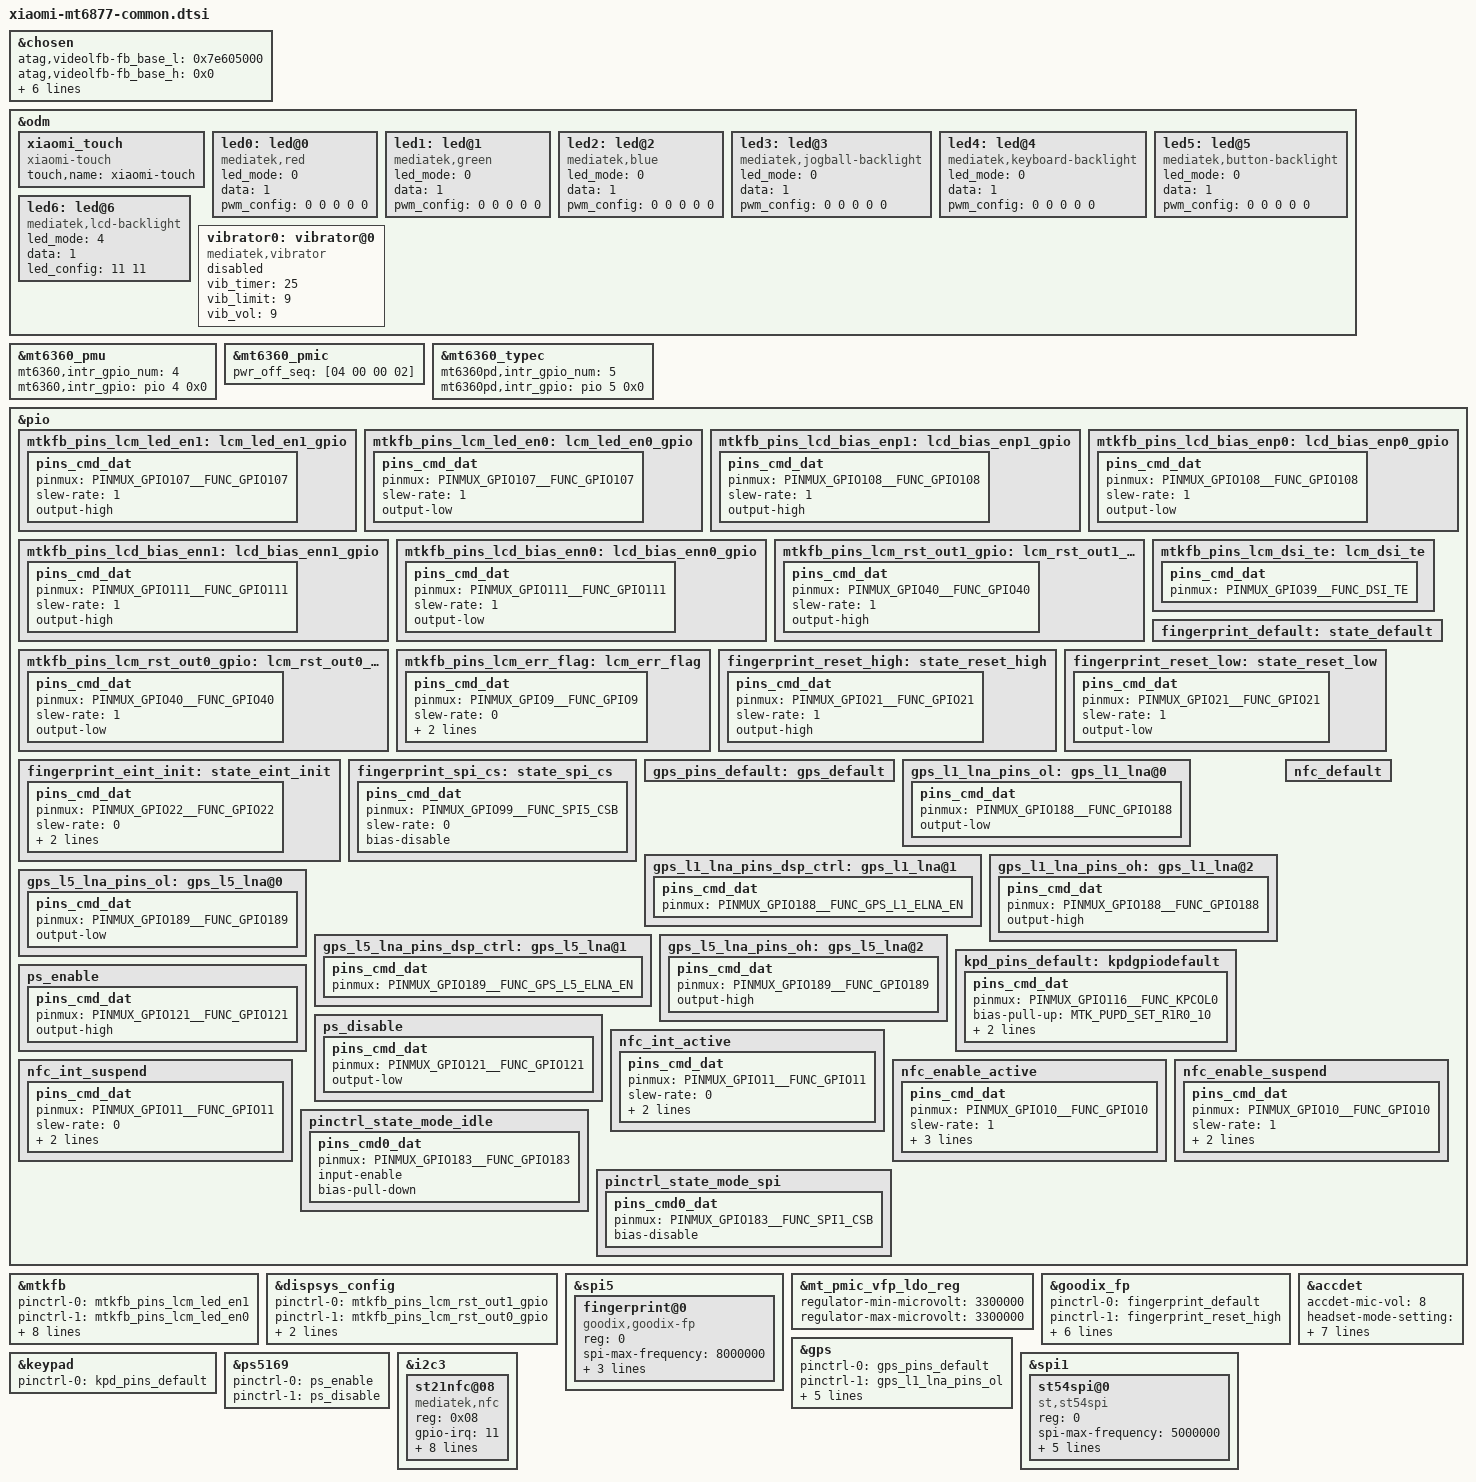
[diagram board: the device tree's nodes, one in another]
// SPDX-License-Identifier: GPL-2.0
/*
 * Copyright (C) 2021 MediaTek Inc.
 * Copyright (C) 2022 XiaoMi, Inc.
 */

/dts-v1/;
/plugin/;
#include <dt-bindings/interrupt-controller/irq.h>
#include <dt-bindings/interrupt-controller/arm-gic.h>
#include <dt-bindings/pinctrl/mt6877-pinfunc.h>

/* chosen */
&chosen {
	atag,videolfb-fb_base_l = <0x7e605000>;
	atag,videolfb-fb_base_h = <0x0>;
	atag,videolfb-islcmfound = <1>;
	atag,videolfb-islcm_inited = <0>;
	atag,videolfb-fps= <6000>;
	atag,videolfb-vramSize= <0x1be0000>;
	atag,videolfb-lcmname=
		"td4330_fhdp_dsi_cmd_auo_rt4831_drv";
};

&odm {
	xiaomi_touch: xiaomi_touch {
		compatible = "xiaomi-touch";
		status = "ok";
		touch,name = "xiaomi-touch";
	};
};

&mt6360_pmu {
	mt6360,intr_gpio_num = <4>; /* direct defined GPIO num */
	mt6360,intr_gpio = <&pio 4 0x0>;
};

&mt6360_pmic {
	pwr_off_seq = [04 00 00 02];
};

&mt6360_typec {
	mt6360pd,intr_gpio_num = <5>; /* direct defined GPIO num */
	mt6360pd,intr_gpio = <&pio 5 0x0>;
};

&pio {
	mtkfb_pins_lcm_led_en1: lcm_led_en1_gpio {
		pins_cmd_dat {
			pinmux = <PINMUX_GPIO107__FUNC_GPIO107>;
			slew-rate = <1>;
			output-high;
		};
	};

	mtkfb_pins_lcm_led_en0: lcm_led_en0_gpio {
		pins_cmd_dat {
			pinmux = <PINMUX_GPIO107__FUNC_GPIO107>;
			slew-rate = <1>;
			output-low;
		};
	};

	mtkfb_pins_lcd_bias_enp1: lcd_bias_enp1_gpio {
		pins_cmd_dat {
			pinmux = <PINMUX_GPIO108__FUNC_GPIO108>;
			slew-rate = <1>;
			output-high;
		};
	};

	mtkfb_pins_lcd_bias_enp0: lcd_bias_enp0_gpio {
		pins_cmd_dat {
			pinmux = <PINMUX_GPIO108__FUNC_GPIO108>;
			slew-rate = <1>;
			output-low;
		};
	};

	mtkfb_pins_lcd_bias_enn1: lcd_bias_enn1_gpio {
		pins_cmd_dat {
			pinmux = <PINMUX_GPIO111__FUNC_GPIO111>;
			slew-rate = <1>;
			output-high;
		};
	};

	mtkfb_pins_lcd_bias_enn0: lcd_bias_enn0_gpio {
		pins_cmd_dat {
			pinmux = <PINMUX_GPIO111__FUNC_GPIO111>;
			slew-rate = <1>;
			output-low;
		};
	};

	mtkfb_pins_lcm_rst_out1_gpio: lcm_rst_out1_gpio {
		pins_cmd_dat {
			pinmux = <PINMUX_GPIO40__FUNC_GPIO40>;
			slew-rate = <1>;
			output-high;
		};
	};

	mtkfb_pins_lcm_rst_out0_gpio: lcm_rst_out0_gpio {
		pins_cmd_dat {
			pinmux = <PINMUX_GPIO40__FUNC_GPIO40>;
			slew-rate = <1>;
			output-low;
		};
	};
	mtkfb_pins_lcm_dsi_te: lcm_dsi_te {
		pins_cmd_dat {
			pinmux = <PINMUX_GPIO39__FUNC_DSI_TE>;
		};
	};
	mtkfb_pins_lcm_err_flag: lcm_err_flag {
		pins_cmd_dat {
			pinmux = <PINMUX_GPIO9__FUNC_GPIO9>;
			slew-rate = <0>;
			bias-pull-up;
			input-enable;
		};
	};
};

&mtkfb {
	pinctrl-names = "lcm_led_en1_gpio", "lcm_led_en0_gpio",
		"lcd_bias_enp1_gpio", "lcd_bias_enp0_gpio",
		"lcd_bias_enn1_gpio", "lcd_bias_enn0_gpio",
		"lcm_rst_out1_gpio", "lcm_rst_out0_gpio",
		"mode_te_te", "err_flag_init";
	pinctrl-0 = <&mtkfb_pins_lcm_led_en1>;
	pinctrl-1 = <&mtkfb_pins_lcm_led_en0>;
	pinctrl-2 = <&mtkfb_pins_lcd_bias_enp1>;
	pinctrl-3 = <&mtkfb_pins_lcd_bias_enp0>;
	pinctrl-4 = <&mtkfb_pins_lcd_bias_enn1>;
	pinctrl-5 = <&mtkfb_pins_lcd_bias_enn0>;
	pinctrl-6 = <&mtkfb_pins_lcm_rst_out1_gpio>;
	pinctrl-7 = <&mtkfb_pins_lcm_rst_out0_gpio>;
	pinctrl-8 = <&mtkfb_pins_lcm_dsi_te>;
	pinctrl-9 = <&mtkfb_pins_lcm_err_flag>;
	status = "okay";
};
&dispsys_config {
	pinctrl-names =
		"lcm_rst_out1_gpio", "lcm_rst_out0_gpio",
		"mode_te_te", "err_flag_init";
	pinctrl-0 = <&mtkfb_pins_lcm_rst_out1_gpio>;
	pinctrl-1 = <&mtkfb_pins_lcm_rst_out0_gpio>;
	pinctrl-2 = <&mtkfb_pins_lcm_dsi_te>;
	pinctrl-3 = <&mtkfb_pins_lcm_err_flag>;
	status = "okay";
};

&odm {
	led0:led@0 {
		compatible = "mediatek,red";
		led_mode = <0>;
		data = <1>;
		pwm_config = <0 0 0 0 0>;
	};
	led1:led@1 {
		compatible = "mediatek,green";
		led_mode = <0>;
		data = <1>;
		pwm_config = <0 0 0 0 0>;
	};
	led2:led@2 {
		compatible = "mediatek,blue";
		led_mode = <0>;
		data = <1>;
		pwm_config = <0 0 0 0 0>;
	};
	led3:led@3 {
		compatible = "mediatek,jogball-backlight";
		led_mode = <0>;
		data = <1>;
		pwm_config = <0 0 0 0 0>;
	};
	led4:led@4 {
		compatible = "mediatek,keyboard-backlight";
		led_mode = <0>;
		data = <1>;
		pwm_config = <0 0 0 0 0>;
	};
	led5:led@5 {
		compatible = "mediatek,button-backlight";
		led_mode = <0>;
		data = <1>;
		pwm_config = <0 0 0 0 0>;
	};
	led6:led@6 {
		compatible = "mediatek,lcd-backlight";
		led_mode = <4>;
		data = <1>;
		led_config = <11 11>;
	};
	vibrator0:vibrator@0 {
		status = "disabled";
		compatible = "mediatek,vibrator";
		vib_timer = <25>;
		vib_limit = <9>;
		vib_vol= <9>;
	};
};

/* FINGERPRINT start */
&spi5 {
	#address-cells = <1>;
	#size-cells = <0>;
	fingerprint@0 {
		compatible = "goodix,goodix-fp";
		reg = <0>;
		spi-max-frequency = <8000000>;
		netlink-event = <30>;
		vfp-supply = <&mt_pmic_vfp_ldo_reg>;
		power-type = <1>;
		status = "okay";
	};
};

&mt_pmic_vfp_ldo_reg {
	regulator-min-microvolt = <3300000>;
	regulator-max-microvolt = <3300000>;
};

&goodix_fp {
	pinctrl-names = "default", "reset_high", "reset_low", "eint_init", "spi_cs";
	pinctrl-0 = <&fingerprint_default>;
	pinctrl-1 = <&fingerprint_reset_high>;
	pinctrl-2 = <&fingerprint_reset_low>;
	pinctrl-3 = <&fingerprint_eint_init>;
	pinctrl-4 = <&fingerprint_spi_cs>;
	fpc,gpio_irq = <&pio 22 0>;
	interrupt-parent = <&pio>;
	interrupts = <22 IRQ_TYPE_EDGE_RISING 22 0>;
	status = "okay";
};

&pio {
	fingerprint_default: state_default {
	};
	fingerprint_reset_high: state_reset_high {
		pins_cmd_dat {
			pinmux = <PINMUX_GPIO21__FUNC_GPIO21>;
			slew-rate = <1>;
			output-high;
		};
	};
	fingerprint_reset_low: state_reset_low {
		pins_cmd_dat {
			pinmux = <PINMUX_GPIO21__FUNC_GPIO21>;
			slew-rate = <1>;
			output-low;
		};
	};
	fingerprint_eint_init: state_eint_init {
		pins_cmd_dat {
			pinmux = <PINMUX_GPIO22__FUNC_GPIO22>;
			slew-rate = <0>;
			bias-pull-up = <MTK_PUPD_SET_R1R0_10>;
			input-schmitt-enable;
		};
	};
	fingerprint_spi_cs: state_spi_cs {
		pins_cmd_dat {
			pinmux = <PINMUX_GPIO99__FUNC_SPI5_CSB>;
			slew-rate = <0>;
			bias-disable;
		};
	};
};
/* FINGERPRINT end */

/* GPS GPIO standardization start */
&pio {
	gps_pins_default: gps_default {
	};
	gps_l1_lna_pins_ol: gps_l1_lna@0 {
		pins_cmd_dat {
			pinmux = <PINMUX_GPIO188__FUNC_GPIO188>;
			output-low;
		};
	};
	gps_l1_lna_pins_dsp_ctrl: gps_l1_lna@1 {
		pins_cmd_dat {
			pinmux = <PINMUX_GPIO188__FUNC_GPS_L1_ELNA_EN>;
		};
	};
	gps_l1_lna_pins_oh: gps_l1_lna@2 {
		pins_cmd_dat {
			pinmux = <PINMUX_GPIO188__FUNC_GPIO188>;
			output-high;
		};
	};
	gps_l5_lna_pins_ol: gps_l5_lna@0 {
		pins_cmd_dat {
			pinmux = <PINMUX_GPIO189__FUNC_GPIO189>;
			output-low;
		};
	};
	gps_l5_lna_pins_dsp_ctrl: gps_l5_lna@1 {
		pins_cmd_dat {
			pinmux = <PINMUX_GPIO189__FUNC_GPS_L5_ELNA_EN>;
		};
	};
	gps_l5_lna_pins_oh: gps_l5_lna@2 {
		pins_cmd_dat {
			pinmux = <PINMUX_GPIO189__FUNC_GPIO189>;
			output-high;
		};
	};
};
&gps {
	pinctrl-names = "default",
		"gps_l1_lna_disable",
		"gps_l1_lna_dsp_ctrl",
		"gps_l1_lna_enable",
		"gps_l5_lna_disable",
		"gps_l5_lna_dsp_ctrl",
		"gps_l5_lna_enable";
	pinctrl-0 = <&gps_pins_default>;
	pinctrl-1 = <&gps_l1_lna_pins_ol>;
	pinctrl-2 = <&gps_l1_lna_pins_dsp_ctrl>;
	pinctrl-3 = <&gps_l1_lna_pins_oh>;
	pinctrl-4 = <&gps_l5_lna_pins_ol>;
	pinctrl-5 = <&gps_l5_lna_pins_dsp_ctrl>;
	pinctrl-6 = <&gps_l5_lna_pins_oh>;
	status = "okay";
};
/* GPS GPIO standardization end */

&accdet {
	/* accdet micbias voltage: 0x09:2.85v 0x08:2.8v 0x07,
	 * 2.7v;0x05,2.5v;0x02,1.9v
	 */
	accdet-mic-vol = <8>;
	/* accdet pwm_width, pwm_thresh, fall_delay, rise_delay
	 * debounce0, debounce1, debounce3, debounce4
	 * eint pwm_width, eint pwm_thresh
	 * eint deb(debounce0, debounce1, debounce2, debounce3), inv_debounce
	 */
	headset-mode-setting = <0x500 0x500 1 0x1f0
				0x800 0x6000 0x20 0x44
				0x4 0x1
				0x5 0x3 0x3 0x5 0xe>;
	accdet-plugout-debounce = <1>;
	/*1:ACC mode, 2:low cost without in bias, 6:low cost with in bias*/
	accdet-mic-mode = <2>;
	/*0--MD_MAX--UP_MAX--DW_MAX*/
	headset-three-key-threshold = <0 80 220 400>;
	headset-three-key-threshold-CDD = <0 121 192 600>;
	/*0--MD_MAX--VOICE_MAX--UP_MAX--DW_MAX*/
	headset-four-key-threshold = <0 58 121 192 400>;

	/* select VTH to 2v and 500k, use internal resitance */
	eint_use_ext_res = <0>;
	status = "okay";
};

/* keypad start */
&keypad {
	pinctrl-names = "default";
	pinctrl-0 = <&kpd_pins_default>;
};

&pio {
	kpd_pins_default: kpdgpiodefault {
		pins_cmd_dat {
			pinmux = <PINMUX_GPIO116__FUNC_KPCOL0>;
			bias-pull-up = <MTK_PUPD_SET_R1R0_10>;
			input-enable;
			input-schmitt-enable;
		};
	};
};
/* keypad end */

&ps5169{
	pinctrl-names = "enable", "disable";
	pinctrl-0 = <&ps_enable>;
	pinctrl-1 = <&ps_disable>;
	status = "okay";
};

/* &fusb340 {
	pinctrl-names = "sel_up", "sel_down";
	pinctrl-0 = <&sel_up>;
	pinctrl-1 = <&sel_down>;
	status = "okay";
};*/

&pio {
	ps_enable: ps_enable {
		pins_cmd_dat {
			pinmux = <PINMUX_GPIO121__FUNC_GPIO121>;
			output-high;
		};
	};

	ps_disable: ps_disable {
		pins_cmd_dat {
			pinmux = <PINMUX_GPIO121__FUNC_GPIO121>;
			output-low;
		};
	};

	/* sel_up: sel_up {
		pins_cmd_dat {
			pinmux = <PINMUX_GPIO6__FUNC_GPIO6>;
			output-high;
		};
	};*/

	/* sel_down: sel_down {
		pins_cmd_dat {
			pinmux = <PINMUX_GPIO6__FUNC_GPIO6>;
			output-low;
		};
	};*/
};

//ST NFC for Mediateck start
&i2c3 {
	st21nfc@08 {
		compatible = "mediatek,nfc";
		reg = <0x08>;
		gpio-irq = <11>;
		gpio-irq-std = <&pio 11 0x00>;
		interrupt-parent = <&pio>;
		interrupts = <11 IRQ_TYPE_LEVEL_HIGH 11 0>;
		gpio-rst = <10>;
		gpio-rst-std = <&pio 10 0x0>;
		interrupt-names = "nfc_irq";
		pinctrl-names = "default", "nfc_active", "nfc_suspend";
		pinctrl-0 = <&nfc_default>;
		pinctrl-1 = <&nfc_int_active &nfc_enable_active>;
		pinctrl-2 = <&nfc_int_suspend &nfc_enable_suspend>;
	};
};
&pio {
	nfc_default: nfc_default {
	};
	nfc_int_active: nfc_int_active {
		pins_cmd_dat {
			pinmux = <PINMUX_GPIO11__FUNC_GPIO11>;
			slew-rate = <0>;
			drive-strength = <MTK_DRIVE_2mA>;
			bias-pull-up;
		};
	};
	nfc_int_suspend: nfc_int_suspend {
		pins_cmd_dat {
			pinmux = <PINMUX_GPIO11__FUNC_GPIO11>;
			slew-rate = <0>;
			drive-strength = <MTK_DRIVE_2mA>;
			bias-pull-up;
		};
	};
	nfc_enable_active: nfc_enable_active {
		pins_cmd_dat {
			pinmux = <PINMUX_GPIO10__FUNC_GPIO10>;
			slew-rate = <1>;
			output-high;
			drive-strength = <MTK_DRIVE_2mA>;
			bias-pull-up=<MTK_PUPD_SET_R1R0_11>;
		};
	};
	nfc_enable_suspend: nfc_enable_suspend {
		pins_cmd_dat {
			pinmux = <PINMUX_GPIO10__FUNC_GPIO10>;
			slew-rate = <1>;
			drive-strength = <MTK_DRIVE_2mA>;
			bias-disable;
		};
	};
};
//NFC end

/* ST54H SPI configuration */
&spi1 {
	st54spi@0 {
		compatible = "st,st54spi";
		reg = <0>;
		spi-max-frequency = <5000000> ;
		/* gpio used as SE_PWR_REQ or SE_nRESET */
		gpio-power_nreset = <8>;
		gpio-power_nreset-std = <&pio 8 0x0>;
		/* Power management mode: none, ST54H (default), ST54J */
		power_mode = "ST54H";
		pinctrl-names = "pinctrl_state_mode_idle", "pinctrl_state_mode_spi";
		pinctrl-0 = <&pinctrl_state_mode_idle>;
		pinctrl-1 = <&pinctrl_state_mode_spi>;
		status = "okay";
	};
};

&pio {
	pinctrl_state_mode_idle: pinctrl_state_mode_idle {
		pins_cmd0_dat {
			pinmux = <PINMUX_GPIO183__FUNC_GPIO183>;
			input-enable;
			bias-pull-down;
		};
	};
	pinctrl_state_mode_spi: pinctrl_state_mode_spi {
		pins_cmd0_dat {
			pinmux = <PINMUX_GPIO183__FUNC_SPI1_CSB>;
			bias-disable;
		};
	};
};
/* ST54H SPI configuration -- end */

#include "ruby-mt6877-touch.dts"
//#include "mediatek/cust_mt6877_camera.dtsi"
/*End of this file, DO NOT ADD ANYTHING HERE*/
